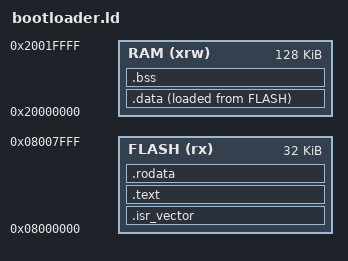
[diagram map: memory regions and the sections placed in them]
/**
 * @file bootloader.ld
 * @brief F407 Bootloader 链接脚本 (32KB Flash)
 *
 * Flash: 0x08000000 - 0x08007FFF (32KB, Sector 0-1)
 * SRAM:  0x20000000 - 0x2001FFFF (128KB, 无 CCM)
 */

MEMORY
{
	FLASH (rx)  : ORIGIN = 0x08000000, LENGTH = 32K
	RAM   (xrw) : ORIGIN = 0x20000000, LENGTH = 128K
}

_estack = ORIGIN(RAM) + LENGTH(RAM);

SECTIONS
{
	.isr_vector :
	{
		. = ALIGN(4);
		KEEP(*(.isr_vector))
		. = ALIGN(4);
	} >FLASH

	.text :
	{
		. = ALIGN(4);
		*(.text)
		*(.text*)
		*(.glue_7)
		*(.glue_7t)
		*(.eh_frame)
		KEEP(*(.init))
		KEEP(*(.fini))
		. = ALIGN(4);
		_etext = .;
	} >FLASH

	.rodata :
	{
		. = ALIGN(4);
		*(.rodata)
		*(.rodata*)
		. = ALIGN(4);
	} >FLASH

	_sidata = LOADADDR(.data);

	.data :
	{
		. = ALIGN(4);
		_sdata = .;
		*(.data)
		*(.data*)
		. = ALIGN(4);
		_edata = .;
	} >RAM AT> FLASH

	.bss :
	{
		. = ALIGN(4);
		_sbss = .;
		*(.bss)
		*(.bss*)
		*(COMMON)
		. = ALIGN(4);
		_ebss = .;
	} >RAM
}
